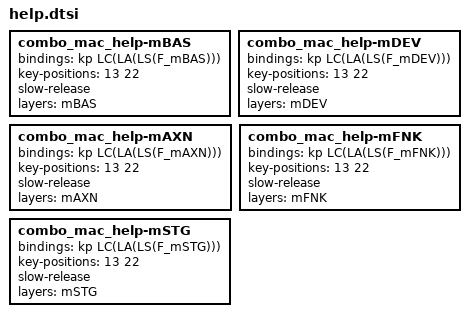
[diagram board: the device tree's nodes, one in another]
combo_mac_help-mBAS {
    bindings = <&kp LC(LA(LS(F_mBAS)))>;
    key-positions = <13 22>;
    slow-release;
    layers = <mBAS>;
};

combo_mac_help-mDEV {
    bindings = <&kp LC(LA(LS(F_mDEV)))>;
    key-positions = <13 22>;
    slow-release;
    layers = <mDEV>;
};

combo_mac_help-mAXN {
    bindings = <&kp LC(LA(LS(F_mAXN)))>;
    key-positions = <13 22>;
    slow-release;
    layers = <mAXN>;
};

combo_mac_help-mFNK {
    bindings = <&kp LC(LA(LS(F_mFNK)))>;
    key-positions = <13 22>;
    slow-release;
    layers = <mFNK>;
};

combo_mac_help-mSTG {
    bindings = <&kp LC(LA(LS(F_mSTG)))>;
    key-positions = <13 22>;
    slow-release;
    layers = <mSTG>;
};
